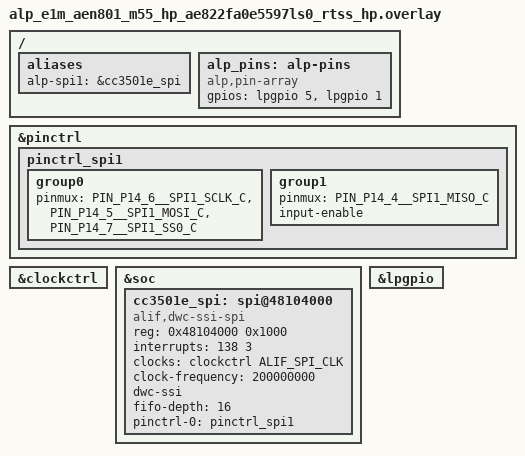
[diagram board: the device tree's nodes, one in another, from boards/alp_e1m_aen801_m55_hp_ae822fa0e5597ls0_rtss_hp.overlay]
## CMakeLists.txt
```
# SPDX-License-Identifier: Apache-2.0

cmake_minimum_required(VERSION 3.20)

find_package(Zephyr REQUIRED HINTS $ENV{ZEPHYR_BASE})
project(iot_fleet_ota LANGUAGES C)

target_sources(app PRIVATE src/main.c)
# Reusable SoM bring-up helper (cc3501e_bridge_bringup): the one-call CC3501E
# bridge init this app uses so alp_wifi_open() can bind to a ready bridge on
# E1M-AEN801 (#2112). Copyable template, same file as examples/aen/aen-cc3501e-*
# -- see src/cc3501e_bridge.h. Built unconditionally; alp_gpio_open()/alp_spi_open()
# fail fast (NULL, no matching backend) on native_sim, so this is a no-op there.
target_sources(app PRIVATE src/cc3501e_bridge.c)
```

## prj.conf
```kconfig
# SPDX-License-Identifier: Apache-2.0
#
# Empty-by-design Kconfig.  The effective build config is the
# overlay alp.conf emitted from board.yaml by `tan build`
# at build time (see scripts/gen_example_alp_conf.py).
#
# mbedtls used to be forced OFF here (and in a native_sim.conf), because
# the pinned mbedtls' ssl_misc.h uses `mbedtls_error_pair_t` with PSA
# crypto off and does not compile.  That is fixed at its root -- the SDK
# now turns mbedtls' PSA core on with mbedtls itself, see
# ALP_SDK_MBEDTLS_PSA_CRYPTO in zephyr/Kconfig.alp-libraries (#2173) --
# so the signature-verify path this demo is about builds with the real
# library on every target, native_sim included.
```

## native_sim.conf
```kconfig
# SPDX-License-Identifier: Apache-2.0
#
# Native-sim Kconfig overlay for iot-fleet-ota.
#
# Loaded LAST via twister's `extra_args: EXTRA_CONF_FILE=...`
# (see ../testcase.yaml), so the settings here win over the
# alp.conf-emitted CONFIG_MBEDTLS=y that `libraries: [mbedtls]`
# pulls into every iot-fleet-ota build.
#
# Why: Zephyr v4.4 ships mbedtls 3.6 + the new tf-psa-crypto
# split.  The upstream library-internal header
# `mbedtls/library/ssl_misc.h` references `mbedtls_error_pair_t`
# before including the type's declaring header; every TU that
# compiles against the SSL portion of mbedtls fails with
# `unknown type name 'mbedtls_error_pair_t'`.  Full integration
# is a v0.6 (TF-M-on-HE + tf-psa-crypto wiring) work item.
#
# On native_sim the framing path is what we want to exercise
# (open(), poll, signature-verify call sites, slot-write call
# site); turning mbedtls off here keeps the build green without
# losing that coverage.  Real-silicon (.aen) builds follow a
# different config stack (TF-M-on-HE core + the mender-mcu-client
# west module) and aren't affected.
CONFIG_MBEDTLS=n
CONFIG_MBEDTLS_BUILTIN=n
CONFIG_MQTT_LIB_TLS=n
```

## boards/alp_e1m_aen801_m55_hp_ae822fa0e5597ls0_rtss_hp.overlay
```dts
/*
 * Copyright (c) 2026 Alp Lab AB
 * SPDX-License-Identifier: Apache-2.0
 *
 * E1M-AEN801 M55-HP overlay for iot-fleet-ota (#2363).  This example's only AEN
 * target is the M55-HP, but it shipped no board overlay, so the SPI1 /
 * CC3501E-bridge pads had no DT node or pinmux there and
 * cc3501e_bridge_bringup() (src/cc3501e_bridge.c, bus_id
 * CC3501E_BRIDGE_SPI_BUS_ID = 1, alp_pins WIFI_EN/NRST) returned
 * ALP_ERR_NOT_PRESENT_ON_THIS_SOC.
 *
 * Byte-for-byte the CC3501E bridge wiring of
 * examples/connectivity/iot-dashboard's M55-HP overlay (#2242), itself the
 * bridge subset of examples/peripheral-io/alp-console's bench-validated
 * M55-HE overlay -- the SoM-internal Alif<->CC3501E SPI1 link + the two
 * host-driven control nets, from metadata/e1m_modules/aen/inter-chip.tsv:
 *   SPI1.SCK P14_6  MOSI P14_5  MISO P14_4   WIFI_EN P15_5  NRST P15_1_FLEX
 * SPI1 @0x48104000 and lpgpio @0x42002000 come from the shared
 * zephyr/dts/alif/ensemble_e8_peripherals.dtsi the HP board dts also
 * includes, so the addresses are the same silicon the M55-HE overlays use.
 *
 * IRQ 138 is carried over from the M55-HE overlays; see their BENCH-TBD
 * comment.
 */
#include <zephyr/dt-bindings/pinctrl/alif-ensemble-pinctrl.h>
#include <zephyr/dt-bindings/gpio/gpio.h>

&pinctrl {
	/* SPI1 master (CC3501E bridge): SCK P14_6 / MOSI P14_5 / MISO P14_4 (alt-2, _C). */
	pinctrl_spi1: pinctrl_spi1 {
		group0 {
			/* SS0 (P14_7) is now peripheral-driven -- the dwc-ssi hardware chip-select,
			 * NOT the old GPIO bodge.  Push-pull output pad like SCLK/MOSI (no input-enable);
			 * the master asserts/deasserts SS0 per transfer (write_ser). */
			pinmux = <PIN_P14_6__SPI1_SCLK_C>, <PIN_P14_5__SPI1_MOSI_C>,
				 <PIN_P14_7__SPI1_SS0_C>;
		};
		group1 {
			pinmux = <PIN_P14_4__SPI1_MISO_C>;
			input-enable;
		};
	};
};

/* P14_7 (CS) is now muxed as SPI1_SS0_C in pinctrl_spi1 -- the dwc-ssi peripheral drives
 * it in hardware per transfer.  The old gpio14 GPIO-bodge controller node is removed: a
 * GPIO claim of P14_7 would fight the SS0 pinctrl mux. */

&clockctrl {
	status = "okay";
};

&soc {
	/* DWC_ssi SPI1 -- the on-SoM CC3501E inter-chip link (NOT the edge SPI0).
	 * 4-wire: SCLK/MOSI/MISO + the hardware SS0 chip-select (P14_7 = SPI1_SS0_C,
	 * declared in pinctrl_spi1 above); clock-frequency = 200 MHz, the real SSI
	 * functional clock (E8 HWRM), so spi_dw_alif skips the failing
	 * clock-control path. */
	cc3501e_spi: spi@48104000 {
		compatible = "alif,dwc-ssi-spi";
		#address-cells = <1>;
		#size-cells = <0>;
		reg = <0x48104000 0x1000>;
		interrupts = <138 3>;          /* BENCH-TBD: SPI1 IRQ */
		clocks = <&clockctrl ALIF_SPI_CLK>;
		/* Real SSI functional clock (E8 HWRM).  Was mis-set to 400000000 here,
		 * which is not a cosmetic error: spi_dw derives BAUDR =
		 * clock-frequency / freq_hz, so a doubled input clock doubles the
		 * divider and HALVES the real SCLK -- this node was running at
		 * 500 kHz while asking for 1 MHz.  Proven via BAUDR scaling and
		 * already corrected in the aen-cc3501e-* overlays. */
		clock-frequency = <200000000>;
		dwc-ssi;
		fifo-depth = <16>;
		/* `rx-delay` IS a real devicetree property
		 * (zephyr/dts/bindings/spi/alif,dwc-ssi-spi.yaml, int, default 0) --
		 * deliberately left UNSET here, not omitted because it doesn't exist.
		 * spi_dw_alif.c writes RX_SAMPLE_DLY (reg 0xF0, ssi_clk cycles at
		 * 200 MHz = 5 ns/cycle) from this property at BOTH init and PM resume
		 * (write_rxdly(dev, info->rx_delay)); spi_dw_configure() never touches
		 * the register outside those two paths. src/cc3501e_bridge.c pokes
		 * RX_SAMPLE_DLY itself once inside cc3501e_bridge_bringup(), after
		 * this node's init already ran, so the unset (0) property here does
		 * not matter today. The overwrite is LATENT, not live: only the
		 * `#if defined CONFIG_PM_DEVICE` resume path (spi_dw_alif.c) would
		 * re-write RX_SAMPLE_DLY from this property, and nothing in this app
		 * enables CONFIG_PM_DEVICE. CC3501E_BRIDGE_RX_SAMPLE_DLY is 4,
		 * silicon-tuned for ~25 MHz on E1M-AEN803 serial 2026W36-0002 --
		 * NOT 6 / ~14.3 MHz, an earlier measurement the header itself
		 * documents as stale and not comparable (see cc3501e_bridge.h's own
		 * correction). */
		pinctrl-0 = <&pinctrl_spi1>;
		pinctrl-names = "default";
		status = "okay";
	};
};

/* LP GPIO island: WIFI_EN (P15_5) + E_WIFI.NRST (P15_1_FLEX) as outputs. */
&lpgpio {
	status = "okay";
};

/ {
	aliases {
		alp-spi1 = &cc3501e_spi;   /* bus_id 1 in cc3501e_bridge_bringup() */
	};

	/* SoM-internal CC3501E control nets, in CC3501E_PIN_* index order. */
	alp_pins: alp-pins {
		compatible = "alp,pin-array";
		gpios = <&lpgpio 5 GPIO_ACTIVE_HIGH>,   /* [0] WIFI_EN     (P15_5)      */
			<&lpgpio 1 GPIO_ACTIVE_HIGH>;   /* [1] E_WIFI.NRST (P15_1_FLEX) */
	};
};
```

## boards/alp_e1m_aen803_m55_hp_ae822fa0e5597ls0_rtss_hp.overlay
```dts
/*
 * Copyright (c) 2026 Alp Lab AB
 * SPDX-License-Identifier: Apache-2.0
 *
 * E1M-AEN803 M55-HP overlay for iot-fleet-ota (#2363).  This example's only AEN
 * target is the M55-HP, but it shipped no board overlay, so the SPI1 /
 * CC3501E-bridge pads had no DT node or pinmux there and
 * cc3501e_bridge_bringup() (src/cc3501e_bridge.c, bus_id
 * CC3501E_BRIDGE_SPI_BUS_ID = 1, alp_pins WIFI_EN/NRST) returned
 * ALP_ERR_NOT_PRESENT_ON_THIS_SOC.
 *
 * Byte-for-byte the CC3501E bridge wiring of
 * examples/connectivity/iot-dashboard's M55-HP overlay (#2242), itself the
 * bridge subset of examples/peripheral-io/alp-console's bench-validated
 * M55-HE overlay -- the SoM-internal Alif<->CC3501E SPI1 link + the two
 * host-driven control nets, from metadata/e1m_modules/aen/inter-chip.tsv:
 *   SPI1.SCK P14_6  MOSI P14_5  MISO P14_4   WIFI_EN P15_5  NRST P15_1_FLEX
 * SPI1 @0x48104000 and lpgpio @0x42002000 come from the shared
 * zephyr/dts/alif/ensemble_e8_peripherals.dtsi the HP board dts also
 * includes, so the addresses are the same silicon the M55-HE overlays use.
 *
 * IRQ 138 is carried over from the M55-HE overlays; see their BENCH-TBD
 * comment.
 */
#include <zephyr/dt-bindings/pinctrl/alif-ensemble-pinctrl.h>
#include <zephyr/dt-bindings/gpio/gpio.h>

&pinctrl {
	/* SPI1 master (CC3501E bridge): SCK P14_6 / MOSI P14_5 / MISO P14_4 (alt-2, _C). */
	pinctrl_spi1: pinctrl_spi1 {
		group0 {
			/* SS0 (P14_7) is now peripheral-driven -- the dwc-ssi hardware chip-select,
			 * NOT the old GPIO bodge.  Push-pull output pad like SCLK/MOSI (no input-enable);
			 * the master asserts/deasserts SS0 per transfer (write_ser). */
			pinmux = <PIN_P14_6__SPI1_SCLK_C>, <PIN_P14_5__SPI1_MOSI_C>,
				 <PIN_P14_7__SPI1_SS0_C>;
		};
		group1 {
			pinmux = <PIN_P14_4__SPI1_MISO_C>;
			input-enable;
		};
	};
};

/* P14_7 (CS) is now muxed as SPI1_SS0_C in pinctrl_spi1 -- the dwc-ssi peripheral drives
 * it in hardware per transfer.  The old gpio14 GPIO-bodge controller node is removed: a
 * GPIO claim of P14_7 would fight the SS0 pinctrl mux. */

&clockctrl {
	status = "okay";
};

&soc {
	/* DWC_ssi SPI1 -- the on-SoM CC3501E inter-chip link (NOT the edge SPI0).
	 * 4-wire: SCLK/MOSI/MISO + the hardware SS0 chip-select (P14_7 = SPI1_SS0_C,
	 * declared in pinctrl_spi1 above); clock-frequency = 200 MHz, the real SSI
	 * functional clock (E8 HWRM), so spi_dw_alif skips the failing
	 * clock-control path. */
	cc3501e_spi: spi@48104000 {
		compatible = "alif,dwc-ssi-spi";
		#address-cells = <1>;
		#size-cells = <0>;
		reg = <0x48104000 0x1000>;
		interrupts = <138 3>;          /* BENCH-TBD: SPI1 IRQ */
		clocks = <&clockctrl ALIF_SPI_CLK>;
		/* Real SSI functional clock (E8 HWRM).  Was mis-set to 400000000 here,
		 * which is not a cosmetic error: spi_dw derives BAUDR =
		 * clock-frequency / freq_hz, so a doubled input clock doubles the
		 * divider and HALVES the real SCLK -- this node was running at
		 * 500 kHz while asking for 1 MHz.  Proven via BAUDR scaling and
		 * already corrected in the aen-cc3501e-* overlays. */
		clock-frequency = <200000000>;
		dwc-ssi;
		fifo-depth = <16>;
		/* `rx-delay` IS a real devicetree property
		 * (zephyr/dts/bindings/spi/alif,dwc-ssi-spi.yaml, int, default 0) --
		 * deliberately left UNSET here, not omitted because it doesn't exist.
		 * spi_dw_alif.c writes RX_SAMPLE_DLY (reg 0xF0, ssi_clk cycles at
		 * 200 MHz = 5 ns/cycle) from this property at BOTH init and PM resume
		 * (write_rxdly(dev, info->rx_delay)); spi_dw_configure() never touches
		 * the register outside those two paths. src/cc3501e_bridge.c pokes
		 * RX_SAMPLE_DLY itself once inside cc3501e_bridge_bringup(), after
		 * this node's init already ran, so the unset (0) property here does
		 * not matter today. The overwrite is LATENT, not live: only the
		 * `#if defined CONFIG_PM_DEVICE` resume path (spi_dw_alif.c) would
		 * re-write RX_SAMPLE_DLY from this property, and nothing in this app
		 * enables CONFIG_PM_DEVICE. CC3501E_BRIDGE_RX_SAMPLE_DLY is 4,
		 * silicon-tuned for ~25 MHz on E1M-AEN803 serial 2026W36-0002 --
		 * NOT 6 / ~14.3 MHz, an earlier measurement the header itself
		 * documents as stale and not comparable (see cc3501e_bridge.h's own
		 * correction). */
		pinctrl-0 = <&pinctrl_spi1>;
		pinctrl-names = "default";
		status = "okay";
	};
};

/* LP GPIO island: WIFI_EN (P15_5) + E_WIFI.NRST (P15_1_FLEX) as outputs. */
&lpgpio {
	status = "okay";
};

/ {
	aliases {
		alp-spi1 = &cc3501e_spi;   /* bus_id 1 in cc3501e_bridge_bringup() */
	};

	/* SoM-internal CC3501E control nets, in CC3501E_PIN_* index order. */
	alp_pins: alp-pins {
		compatible = "alp,pin-array";
		gpios = <&lpgpio 5 GPIO_ACTIVE_HIGH>,   /* [0] WIFI_EN     (P15_5)      */
			<&lpgpio 1 GPIO_ACTIVE_HIGH>;   /* [1] E_WIFI.NRST (P15_1_FLEX) */
	};
};
```

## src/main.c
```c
/*
 * Copyright 2026 Alp Lab AB
 * SPDX-License-Identifier: Apache-2.0
 *
 * iot-fleet-ota -- secure OTA firmware update.
 *
 * The production-readiness proof: "how do we update 10k units in
 * the field?".  Answer:
 *
 *   1. Every 60 s the device polls a Mender server over HTTPS.
 *      The server (separate repo, see docs/ota.md) answers with
 *      either "no deployment" or a signed firmware manifest +
 *      artefact URL.
 *
 *   2. The device downloads the artefact and verifies its
 *      ECDSA-P256 signature.  The verifying public key was
 *      compiled into the bootloader at provisioning time from
 *      the OPTIGA Trust M's secure NVM (slot 0xE0F0).  The
 *      private half *never* leaves the SoM -- it lives in the
 *      OPTIGA's tamper-resistant store and only the signing
 *      host with physical access to a provisioned OPTIGA can
 *      produce a signature that this device will accept.  See
 *      docs/secure-boot.md "Signing key lifecycle".
 *
 *   3. The verified bytes are written to flash.  On a genuine
 *      two-slot AEN target this step writes the inactive slot
 *      (slot-B if currently booted from slot-A, vice versa) and
 *      arms MCUboot's swap-using-scratch "test pending" trailer
 *      so the next reboot tries the new image with a one-shot
 *      fall-back-if-not-confirmed flag set.
 *
 *   4. k_reboot().  On a two-slot target MCUboot validates the
 *      signature *again* at boot, swaps, and hands off to the
 *      new image.
 *
 *   5. On a two-slot target, the new image must call
 *      boot_set_confirmed() within its health-check window or
 *      MCUboot rolls back to the previous slot on the next
 *      reboot -- a watchdog-friendly safety net: an OTA that
 *      bricks the device is automatically reversed.
 *
 * [STATUS] On this SKU (E1M-AEN801), steps 3-5 above describe the
 * general two-slot AEN design, not what runs here.  MCUboot boots
 * single-app on this SoM (CONFIG_SINGLE_APPLICATION_SLOT=y,
 * #1069/#1413) -- both M55 cores share the same physical App MRAM,
 * so there is no inactive slot to write into and no swap-with-revert
 * to arm.  slot0 is the running XIP image (docs/secure-boot.md),
 * and the maintainer decision on #1069 explicitly DEFERS OTA on
 * both cores: no secondary/scratch slot means there is no supported
 * place to stage a new image, and overwriting the running slot0
 * in place is not a supported flow.  MCUboot still re-verifies
 * slot0's signature on every boot and halts on a failed check, but
 * *applying* an update is not implemented on this SKU today.  See
 * board.yaml and docs/secure-boot.md.  The write-and-reboot path
 * needs a two-slot AEN target, which none of the qualified boards
 * are today.
 *
 * Three layers of defence
 * =======================
 *   - Wire:    HTTPS / TLS (mbedtls) protects the download from
 *              MITM tampering.
 *   - Image:   ECDSA-P256 signature gates *acceptance* into the
 *              flash; an attacker with the server's keys still
 *              can't produce a passing artefact without the
 *              OPTIGA-locked private key.
 *   - Boot:    MCUboot re-verifies at every boot; a two-slot AEN
 *              target atomic-swaps and recovers mid-write power
 *              loss via the scratch slot, while this SKU's
 *              single-app layout halts on a failed re-verify (see
 *              [STATUS] above).
 *
 * Targets ALL E1M-X SoMs (the trust model is shared; only the
 * download transport varies -- HTTPS on AEN via the CC3501E,
 * Ethernet on V2N family, optional cellular on customer fork).
 *
 * What runs under native_sim
 * ==========================
 * Mender's HTTPS calls aren't reachable from the framing test,
 * the OPTIGA isn't present, and MCUboot isn't running underneath.
 * The demo stubs out the network and signature paths, prints
 * each protocol stage so a CI observer can confirm the framing
 * is intact, and exits cleanly.  main() still calls
 * cc3501e_bridge_bringup() (#2112, same template every
 * examples/aen/aen-cc3501e-* app uses) so alp_wifi_open() below has a
 * live bridge handle to bind to on AEN HiL -- on native_sim that
 * bring-up fails fast (ALP_ERR_NOT_PRESENT_ON_THIS_SOC) and Stage 1
 * falls through to the same NULL/NOSUPPORT framing path as before.
 *
 * What runs on AEN HiL
 * ====================
 * Real polling against a staged Mender server; real ECDSA-P256
 * verification via mbedtls today, with OPTIGA-backed PSA hardware
 * acceleration planned once that driver lands.  Applying the
 * verified artefact -- Stage 4's flash write and Stage 5's reboot
 * -- is NOT part of the qualified HiL path on this SKU: OTA is
 * DEFERRED on both cores (#1069), there is no staging slot, and
 * self-overwriting the running slot0 is not a supported flow.
 * Stages 4-5 below print what the flow *would* do and stop short
 * of touching slot0 (see [STATUS]).
 */

#include <stdio.h>
#include <string.h>

#include <zephyr/kernel.h>

#include "alp/iot.h"
#include "alp/security.h"
#include "alp/storage.h"
#include "cc3501e_bridge.h" /* cc3501e_bridge_bringup() -- the SoM bring-up template, #2112 */

/* Mender poll cadence.  60 s is aggressive for a fleet (typical
 * production cadence is 15-60 minutes); the short interval here
 * matches the demo intent of "show one full cycle quickly". */
#define OTA_POLL_INTERVAL_S 60u

/* The OTA server URL gets baked in at provisioning time.  In a
 * real fleet customers point this at their own Mender instance;
 * the placeholder here is documentation only. */
#define MENDER_SERVER_URL "https://mender.example.alplab.ai"

/* ECDSA-P256 signatures are 64 bytes raw / ~72 bytes DER.  We
 * use the raw form on the wire to match imgtool's signed
 * artefact encoding. */
#define SIG_ECDSA_P256_BYTES 64u

/* Manifest payload size cap.  Mender's deployment JSON is small
 * (artefact URL, checksum, signature, target slot, version
 * string) -- 1 KiB is generous. */
#define MANIFEST_MAX_BYTES 1024u

/* On E1M-AEN801 with the CC3501E bridge attached, alp_wifi_connect() routes
 * to the CC3501E backend (src/backends/wifi/cc3501e.c), and the bridge's own
 * worst case for one STA connect is 10s Wlan_RoleUp + 30s L2 association +
 * a 30s DHCP-lease poll (hal/ti/cc3501e_hw_ti_wifi.c) = 70s. On other Wi-Fi
 * backends this value is only an upper bound, not a derived worst case. */
#define WIFI_CONNECT_TIMEOUT_MS 75000u

/* ----------------------------------------------------------------- */
/* Stage 1: connect to the Mender server                              */
/* ----------------------------------------------------------------- */

/**
 * @brief Open the Wi-Fi station + raise it to associated state.
 *
 * On native_sim the open returns NULL with NOSUPPORT and the
 * framing path returns false -- which is the expected behaviour
 * documented in <alp/iot.h>'s NOSUPPORT contract.
 */
static bool fleet_wifi_up(void)
{
	printf("[ota] stage 1: bringing Wi-Fi station up\n");
	alp_wifi_t *w = alp_wifi_open();
	if (w == NULL) {
		printf("[ota]   alp_wifi_open -> NULL (native_sim: NOSUPPORT;"
		       " HiL pre-DT: NOT_READY)\n");
		return false;
	}
	/* On real silicon the credentials come from the EEPROM
     * factory manifest (alp_hw_info_t.wifi_*) so the same
     * binary works across fleet units.  Hardcoded for the
     * framing demo. */
	const alp_wifi_credentials_t creds = {
		.ssid = "fleet-ssid",
		.psk  = "fleet-psk",
	};
	const alp_status_t rc = alp_wifi_connect(w, &creds, WIFI_CONNECT_TIMEOUT_MS);
	if (rc != ALP_OK) {
		printf("[ota]   alp_wifi_connect -> %d\n", (int)rc);
		alp_wifi_close(w);
		return false;
	}
	printf("[ota]   Wi-Fi associated -- ready for HTTPS poll\n");
	alp_wifi_close(w); /* HTTPS client re-uses the station;
                         * keep the handle short-lived for the
                         * framing test. */
	return true;
}

/* ----------------------------------------------------------------- */
/* Stage 2: poll Mender's HTTPS deployment endpoint                   */
/* ----------------------------------------------------------------- */

/**
 * @brief Ask the Mender server whether a deployment is pending.
 *
 * The real Mender protocol is HTTPS GET on
 * /api/devices/v1/deployments/device/deployments/next plus a
 * device-identity body.  On native_sim we stub the call and
 * print the protocol stage.
 *
 * @param[out] manifest_out   Manifest bytes (on real silicon).
 * @param[in]  manifest_cap   Buffer capacity.
 * @param[out] manifest_len   Bytes written.
 *
 * @return true if a deployment is pending, false if not.
 */
static bool fleet_poll_for_update(uint8_t *manifest_out, size_t manifest_cap, size_t *manifest_len)
{
	(void)manifest_out;
	(void)manifest_cap;
	if (manifest_len != NULL) {
		*manifest_len = 0u;
	}
	printf("[ota] stage 2: polling %s for deployment\n", MENDER_SERVER_URL);
	printf("[ota]   GET /api/devices/v1/deployments/.../next"
	       " (stubbed on native_sim)\n");
	/* On native_sim no manifest comes back -- the framing demo
     * exits the poll loop here.  On HiL the mender-mcu-client
     * fills the buffer with the deployment JSON. */
	return false;
}

/* ----------------------------------------------------------------- */
/* Stage 3: verify ECDSA-P256 signature                               */
/* ----------------------------------------------------------------- */

/**
 * @brief Verify the artefact signature against the OPTIGA-locked
 *        public key.
 *
 * On AEN-Zephyr this routes through mbedtls's PSA Crypto API today.
 * OPTIGA Trust M acceleration is the planned PSA backend; the
 * verifying key is the public half of the OPTIGA's slot 0xE0F0,
 * compiled into the MCUboot bootloader at production provisioning
 * time.
 *
 * On native_sim the function returns true (framing only); on
 * HiL a tampered artefact returns false and the OTA is aborted
 * before any flash is touched.
 *
 * @param[in] image      Artefact bytes.
 * @param[in] image_len  Artefact length.
 * @param[in] sig        Signature bytes (raw P-256, 64 B).
 * @param[in] sig_len    Signature length.
 *
 * @return true on signature pass, false otherwise.
 */
static bool
fleet_verify_signature(const uint8_t *image, size_t image_len, const uint8_t *sig, size_t sig_len)
{
	(void)image;
	(void)image_len;
	(void)sig;
	(void)sig_len;
	printf("[ota] stage 3: verifying ECDSA-P256 signature\n");
	printf("[ota]   public key = OPTIGA Trust M slot 0xE0F0"
	       " (compiled into MCUboot)\n");
	printf("[ota]   alp_hash + ECDSA-P256 verify"
	       " (stubbed on native_sim)\n");
	return true;
}

/* ----------------------------------------------------------------- */
/* Stage 4: read flash geometry (no write -- see [STATUS])            */
/* ----------------------------------------------------------------- */

/**
 * @brief Open the flash handle and report geometry for the
 *        would-be artefact write.
 *
 * On a two-slot AEN target, MCUboot lays out slot-A and slot-B
 * back-to-back in the internal flash and this step writes the
 * inactive one.  On this SKU (E1M-AEN801) MCUboot boots
 * single-app (see [STATUS] at the top of this file): OTA apply is
 * DEFERRED (#1069) -- there is no inactive slot to write, and
 * self-overwriting the running slot0 in place is not a supported
 * flow.  alp_storage_open(INTERNAL_FLASH) gives the raw flash
 * handle for framing purposes only; this function stops after
 * reading geometry and never erases or writes a byte of slot0.
 */
static bool fleet_write_verified_image(const uint8_t *image, size_t image_len)
{
	(void)image;
	(void)image_len;
	printf("[ota] stage 4: reading flash geometry (no write -- see [STATUS])\n");
	alp_storage_t *s = alp_storage_open(&(alp_storage_config_t){
	    .kind        = ALP_STORAGE_KIND_INTERNAL_FLASH,
	    .instance_id = 0u,
	});
	if (s == NULL) {
		printf("[ota]   alp_storage_open(INTERNAL_FLASH) -> NULL"
		       " (last_err=%d)\n",
		       (int)alp_last_error());
		return false;
	}
	alp_storage_info_t info = { 0 };
	const alp_status_t rc   = alp_storage_get_info(s, &info);
	if (rc == ALP_OK) {
		printf("[ota]   flash geometry: %llu bytes total,"
		       " erase=%u write=%u\n",
		       (unsigned long long)info.total_bytes,
		       (unsigned)info.erase_size,
		       (unsigned)info.block_size);
	}
	/* A two-slot AEN target would loop over MENDER_CHUNK_SIZE
     * windows here, erase the inactive slot, write each chunk,
     * and feed the watchdog.  On this SKU that loop has no
     * supported destination (see [STATUS]), so the demo -- on
     * both native_sim and HiL -- stops at the open()+info read
     * and never issues an erase or write. */
	printf("[ota]   (no supported destination on this SKU -- see [STATUS];"
	       " stopping after geometry read)\n");
	alp_storage_close(s);
	return true;
}

/* ----------------------------------------------------------------- */
/* Stage 5: no write -> no reboot on this SKU (see [STATUS])          */
/* ----------------------------------------------------------------- */

/**
 * @brief Trigger a reboot -- the step that would follow a real
 *        write on a two-slot target.
 *
 * On a two-slot AEN target this would set MCUboot's "test
 * pending" flag in the slot trailer: swap-using-scratch treats
 * it as one-shot -- the next boot tries the new slot, but if
 * boot_set_confirmed() isn't called in the new image's
 * health-check window, the *following* boot rolls back to the
 * previous slot, and mid-swap power loss recovers via the
 * scratch sector.  On this SKU (E1M-AEN801) MCUboot boots
 * single-app (see [STATUS] at the top of this file): there is no
 * slot trailer to arm, no rollback target, and (since Stage 4
 * never wrote a new image -- OTA apply is DEFERRED, #1069) no new
 * image to boot into either.  A reboot here would simply
 * re-verify the unchanged slot0 and halt if that check ever
 * fails.  See docs/secure-boot.md "Failure modes".
 */
static void fleet_finish_update_and_reboot(void)
{
	printf("[ota] stage 5: no new image to boot into (see [STATUS])\n");
	printf("[ota]   skipping reboot -- OTA apply is DEFERRED on this SKU (#1069)\n");
}

/* ----------------------------------------------------------------- */
/* Orchestrator                                                       */
/* ----------------------------------------------------------------- */

/**
 * @brief One iteration of the OTA poll loop.
 *
 * On native_sim the poll returns "no deployment" and the loop
 * exits.  On HiL the loop runs forever at OTA_POLL_INTERVAL_S
 * cadence; when a deployment lands the function still returns
 * false without rebooting -- OTA apply is DEFERRED on this SKU
 * (#1069, see [STATUS] at the top of this file), so there is no
 * write and no k_reboot() call.
 *
 * @return true to keep looping, false to exit.
 */
static bool fleet_ota_tick(void)
{
	if (!fleet_wifi_up()) {
		return true; /* try again next tick */
	}

	uint8_t manifest[MANIFEST_MAX_BYTES];
	size_t  manifest_len = 0u;
	if (!fleet_poll_for_update(manifest, sizeof manifest, &manifest_len)) {
		printf("[ota]   no deployment pending -- sleeping %us\n", (unsigned)OTA_POLL_INTERVAL_S);
		return true;
	}

	/* On HiL the manifest carries the artefact URL + signature.
     * The download happens chunked through the mender-mcu-client
     * (which calls back into this app's "verify-and-write" path
     * once the bytes are buffered).  The flow below is the
     * happy-path skeleton. */
	const uint8_t *image   = manifest; /* placeholder */
	const size_t   img_len = manifest_len;
	const uint8_t *sig     = manifest; /* placeholder */
	const size_t   sig_len = SIG_ECDSA_P256_BYTES;

	if (!fleet_verify_signature(image, img_len, sig, sig_len)) {
		printf("[ota]   signature verification FAILED -- discarding\n");
		return true;
	}
	if (!fleet_write_verified_image(image, img_len)) {
		printf("[ota]   slot write failed -- aborting deployment\n");
		return true;
	}
	fleet_finish_update_and_reboot();
	return false; /* no reboot: OTA apply is DEFERRED on this SKU (#1069) */
}

int main(void)
{
	printf("[ota] alp-sdk iot-fleet-ota demo\n");
	printf("[ota]   trust: OPTIGA Trust M (slot 0xE0F0) +"
	       " ECDSA-P256 + MCUboot single-app (see board.yaml [STATUS])\n");
	printf("[ota]   transport: HTTPS poll to %s (Mender protocol)\n", MENDER_SERVER_URL);

	/* STATIC, not a local -- cc3501e_t embeds several
	 * ALP_CC3501E_MAX_PAYLOAD scratch buffers; see cc3501e_bridge.h.
	 * Bring the bridge up ONCE, before the poll loop -- not inside
	 * fleet_wifi_up(), which runs every tick and would otherwise
	 * re-run the WIFI_EN/nRESET reset sequence on every poll. */
	static cc3501e_t bridge    = { 0 };
	alp_status_t     bridge_rc = cc3501e_bridge_bringup(&bridge);
	printf("[ota]   cc3501e_bridge_bringup -> %d\n", (int)bridge_rc);

	for (;;) {
		if (!fleet_ota_tick()) {
			break;
		}
#ifdef CONFIG_BOARD_NATIVE_SIM
		break; /* one iteration is enough for the framing test */
#else
		k_sleep(K_SECONDS(OTA_POLL_INTERVAL_S));
#endif
	}

	printf("[ota] done\n");
	return 0;
}
```

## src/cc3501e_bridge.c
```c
/*
 * SPDX-License-Identifier: Apache-2.0
 * Copyright 2026 Alp Lab AB
 *
 * E1M-AEN SoM CC3501E bridge bring-up helper -- see cc3501e_bridge.h.
 *
 * The final reset is warm-aware.  cc3501e_reset() drops WIFI_EN for 50 ms, a
 * supply cold cycle; on a CC3501E that is already running (an activated unit with
 * vendor_sbl_container_enable=1 may then never relaunch) that must not happen on a
 * mere re-run or warm reset of the application.  So when WIFI_EN already reads high
 * AND the chip answers a PING the bring-up resets through nRESET only
 * (cc3501e_hard_reset()), and uses cc3501e_reset() only from WIFI_EN low or, as a
 * last resort, from a chip that stays silent through an nRESET-only reset.  WIFI_EN
 * reading high alone is not trusted: a pull-up would make every power-on look warm
 * (whether the module has one is an open question, issue #2797).
 */

#include "cc3501e_bridge.h"

#include <stdio.h>

#if defined(CONFIG_SOC_AE822FA0E5597LS0_RTSS_HE) || defined(CONFIG_SOC_AE822FA0E5597LS0_RTSS_HP)
#include <zephyr/arch/cpu.h>
#include <zephyr/devicetree.h>
#include <zephyr/sys/sys_io.h>
/*
 * AEN LP-pad mux (Alif Ensemble E8, both M55-HE and M55-HP cores).  WIFI_EN
 * (P15_5) and nRESET (P15_1) are on the Alif LP-GPIO island, bound by the
 * generic snps,designware-gpio driver which does NOT apply Alif pinctrl --
 * so the LP pads stay un-muxed and their output drivers OFF (confirmed on
 * silicon on M55-HE: WIFI_EN never powers the CC3501E until these regs are
 * set).  0x23 = the Alif GPIO-output pad config (driver + read-enable +
 * drive strength).  TODO: drop this raw poke once the Alif GPIO backend
 * muxes the LP island via pinctrl.
 *
 * ALIF_LPGPIO_PADCTRL_BASE (0x42007000) is not an M55-HE-local address: the
 * shared upstream `pin-controller@1a603000` node (ensemble_common.dtsi,
 * included by both cores' SoC dtsi) declares this exact window as its
 * second `reg` range, and `alp_e1m_aen801_m55_hp-pinctrl.dtsi` already
 * muxes a different LP-GPIO pad (P15_0, RTC_ALARM) from the M55-HP pinctrl
 * driver through it, so the poke below is equally applicable on M55-HP.
 * Running it on M55-HP is NOT bench-proven -- only running it on M55-HE has
 * been confirmed on silicon.
 */
#define ALIF_LPGPIO_PADCTRL_BASE 0x42007000u
#define ALIF_PAD_GPIO_OUTPUT     0x23u
/* Latch WIFI_EN (P15_5) HIGH in the port's data register while the pad is still an
 * INPUT.  Switching the direction afterwards then drives the already-high level; the
 * other order (direction first, value second -- what gpio_dw's configure does even
 * with an init flag) drives whatever DR holds, and with DR bit 5 = 0 that glitches
 * the supply of a running chip low.  DR is written directly (read-modify-write, the
 * same access gpio_dw's port_set_bits_raw makes) so this template stays on the
 * portable <alp/...> headers: SWPORTA_DR is offset 0x00 of the DesignWare GPIO block
 * (zephyr drivers/gpio/gpio_dw_registers.h), the block base is the `lpgpio` node's
 * reg, and the LP-GPIO clock is already on because alp_gpio_open() opened the pin. */
#define DW_GPIO_SWPORTA_DR 0x00u
static void aen_wifi_en_latch_high(void)
{
	const mem_addr_t dr = DT_REG_ADDR(DT_NODELABEL(lpgpio)) + DW_GPIO_SWPORTA_DR;

	sys_write32(sys_read32(dr) | (1u << 5), dr);
}

static void aen_lp_pads_enable_output(void)
{
	sys_write32(ALIF_PAD_GPIO_OUTPUT, ALIF_LPGPIO_PADCTRL_BASE + 5u * 4u); /* P15_5 WIFI_EN */
	sys_write32(ALIF_PAD_GPIO_OUTPUT, ALIF_LPGPIO_PADCTRL_BASE + 1u * 4u); /* P15_1 nRESET  */
}
#else
static inline void aen_lp_pads_enable_output(void)
{
}
static inline void aen_wifi_en_latch_high(void)
{
}
#endif

alp_status_t cc3501e_bridge_bringup(cc3501e_t *fw)
{
	if (fw == NULL) {
		return ALP_ERR_INVAL;
	}

	/* 1. Control pins: WIFI_EN (supply gate) + nRESET.  These are Alif LP-GPIO
	 *    pads, not E1M edge pads -- the SoM owns them. */
	alp_gpio_t *wifi_en = alp_gpio_open(CC3501E_BRIDGE_PIN_WIFI_EN);
	alp_gpio_t *nrst    = alp_gpio_open(CC3501E_BRIDGE_PIN_NRST);
	if (wifi_en == NULL || nrst == NULL) {
		if (wifi_en != NULL) {
			alp_gpio_close(wifi_en);
		}
		if (nrst != NULL) {
			alp_gpio_close(nrst);
		}
		return ALP_ERR_NOT_PRESENT_ON_THIS_SOC;
	}
	aen_lp_pads_enable_output();
	/* Sample the supply gate BEFORE touching its direction.  High is only a HINT
	 * that the chip may be powered -- an external pull-up on WIFI_EN would make every
	 * power-on read high (whether the module has one is an OPEN QUESTION; the
	 * netlist has not been checked), so the decision below also needs a PING. */
	bool wifi_was_high = false;
	(void)alp_gpio_read(wifi_en, &wifi_was_high);
	if (wifi_was_high) {
		/* Latch the level in DR first so the direction change cannot glitch it low. */
		aen_wifi_en_latch_high();
	}
	(void)alp_gpio_configure(wifi_en, ALP_GPIO_OUTPUT, ALP_GPIO_PULL_NONE);
	(void)alp_gpio_configure(nrst, ALP_GPIO_OUTPUT, ALP_GPIO_PULL_NONE);

	/* 2. Inter-chip SPI (Alif = master).  CS is the dwc-ssi hardware SS0
	 *    muxed on P14_7; the app passes ALP_SPI_NO_CS so no software GPIO CS
	 *    is installed and the SPI controller drives SS0 per transfer.  Mode 0
	 *    matches the CC3501E vendor image frameFormat. */
	alp_spi_t *spi = alp_spi_open(&(alp_spi_config_t){
	    .bus_id        = CC3501E_BRIDGE_SPI_BUS_ID,
	    .freq_hz       = CC3501E_BRIDGE_SPI_FREQ_HZ,
	    .mode          = ALP_SPI_MODE_0,
	    .bits_per_word = 8u,
	    .cs_pin_id     = ALP_SPI_NO_CS,
	});
	if (spi == NULL) {
		alp_gpio_close(wifi_en);
		alp_gpio_close(nrst);
		return ALP_ERR_NOT_PRESENT_ON_THIS_SOC;
	}

#if CC3501E_BRIDGE_RX_SAMPLE_DLY > 0
	/* Raise the SCLK past 1 MHz: the DW SSI RX_SAMPLE_DLY register (0xf0) delays
	 * the MISO capture point by N ssi_clk cycles to cover the on-SoM trace + crossed
	 * data round-trip.  Zephyr spi_dw never writes it (leaves 0), so without this
	 * >1 MHz mis-samples MISO (cold reqhdr_rx=0xFFFFFFFF).  Written with SSI disabled
	 * (SSIENR=0); persists across the driver's per-transfer configure.  Value is
	 * silicon-tuned -- sweep CC3501E_BRIDGE_RX_SAMPLE_DLY at the target SCLK.
	 *
	 * SWEEP TRAP -- read before setting the constant to 0: the `#if > 0` above
	 * compiles this block out, so 0 does not mean "no delay", it means the SPI
	 * node's `rx-delay` devicetree value is left in place.  aen-cc3501e-bringup
	 * and aen-evk-demo declare rx-delay = <2>, so a naive N=0 sweep point on
	 * those two silently measures 2.  Read 0x481040F0 back to see what the link
	 * is actually running at. */
	{
		volatile uint32_t *ssienr =
		    (volatile uint32_t *)(uintptr_t)(CC3501E_BRIDGE_SPI1_BASE + 0x08u);
		volatile uint32_t *rsd = (volatile uint32_t *)(uintptr_t)(CC3501E_BRIDGE_SPI1_BASE + 0xf0u);
		uint32_t           en  = *ssienr;
		*ssienr                = 0u;
		*rsd                   = (uint32_t)CC3501E_BRIDGE_RX_SAMPLE_DLY;
		*ssienr                = en;
	}
#endif

	/* 3. Bind the bus + control pins; attach the GPIO proxy (proxied E1M IOs then
	 *    route over the bridge); run the power + reset sequence (TI SWRU626 + the
	 *    Puya cold-boot hard-reset workaround).  Leaves WIFI_EN HIGH. */
	(void)cc3501e_init(fw, spi);
	fw->enable_pin = wifi_en;
	fw->reset_pin  = nrst;
	/* READY (CC35 GPIO17) is NOT wired here by default on this R2 module --
	 * see chips/cc3501e/cc3501e_core.c's cc3501e_reply_gate() comment for the
	 * pin-routing fact, the bench evidence, and how a board that genuinely
	 * wires it can opt back in via fw->ready_pin. */
#ifdef CONFIG_ALP_SDK_GPIO_CC3501E_PROXY
	(void)alp_gpio_cc3501e_attach(fw);
#endif
#ifdef CONFIG_ALP_SDK_WIFI_CC3501E
	(void)alp_wifi_cc3501e_attach(fw);
#endif
#ifdef CONFIG_ALP_SDK_BLE_CC3501E
	(void)alp_ble_cc3501e_attach(fw);
#endif
	/* One line naming the path taken, so a log shows whether the supply was cycled. */
	if (!wifi_was_high) {
		printf("[cc3501e_bridge] WIFI_EN low: cold power-up (cc3501e_reset)\n");
		return cc3501e_reset(fw); /* supply low: the full cold-boot sequence */
	}
	/* WIFI_EN reads high.  Warm = the chip ANSWERS a PING; a pull-up alone proves
	 * nothing.  Warm: nRESET only, never a WIFI_EN toggle. */
	if (cc3501e_ping(fw) == ALP_OK) {
		printf("[cc3501e_bridge] WIFI_EN high, PING ok: warm, nRESET only\n");
		return cc3501e_hard_reset(fw);
	}
	/* High but silent: powered-and-hung, or unpowered behind a pull-up.  Try the
	 * nRESET-only reset first (safe for a powered chip); only if the chip still does
	 * not answer is the supply cycled -- the last resort, taken from a chip that is
	 * already unresponsive. */
	if (cc3501e_hard_reset(fw) == ALP_OK && cc3501e_ping(fw) == ALP_OK) {
		printf("[cc3501e_bridge] WIFI_EN high, silent: recovered by nRESET only\n");
		return ALP_OK;
	}
	printf("[cc3501e_bridge] WIFI_EN high, silent after nRESET: supply cycle (cc3501e_reset)\n");
	return cc3501e_reset(fw);
}
```
